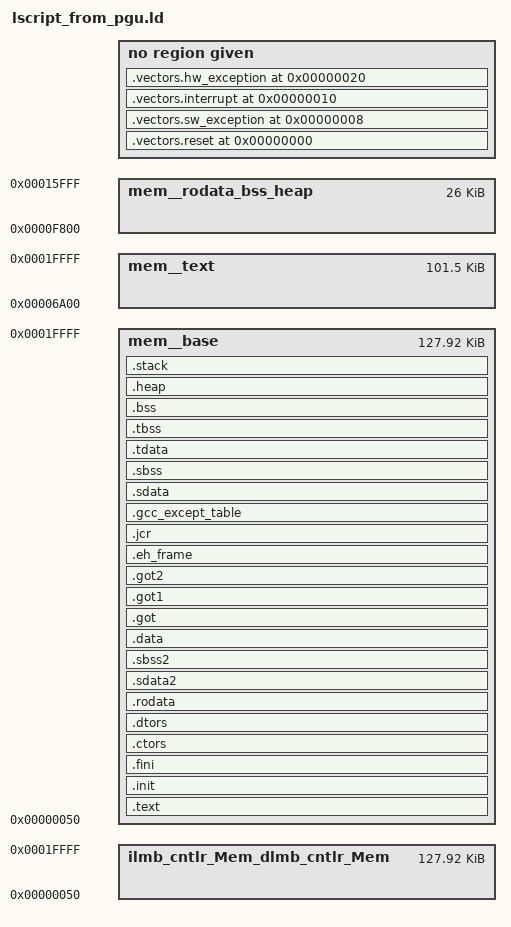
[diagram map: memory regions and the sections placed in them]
/*******************************************************************/
/*                                                                 */
/* This file is automatically generated by linker script generator.*/
/*                                                                 */
/* Version:                                 */
/*                                                                 */
/* Copyright (c) 2010-2016 Xilinx, Inc.  All rights reserved.      */
/*                                                                 */
/* Description : MicroBlaze Linker Script                          */
/*                                                                 */
/*******************************************************************/

_STACK_SIZE = DEFINED(_STACK_SIZE) ? _STACK_SIZE : 0x340;
_HEAP_SIZE = DEFINED(_HEAP_SIZE) ? _HEAP_SIZE : 0x18;

/* Define Memories in the system */

MEMORY
{
   ilmb_cntlr_Mem_dlmb_cntlr_Mem : ORIGIN = 0x50, LENGTH = 0x1FFB0
   mem__rodata_bss_heap  : ORIGIN = 0x0F800, LENGTH = 0x06800
   mem__text  : ORIGIN = 0x06A00, LENGTH = 0x19600
   mem__base  : ORIGIN = 0x50, LENGTH = 0x1FFB0
}

/* Specify the default entry point to the program */

ENTRY(_start)

/* Define the sections, and where they are mapped in memory */

SECTIONS
{
.vectors.reset 0x0 : {
   KEEP (*(.vectors.reset))
} 

.vectors.sw_exception 0x8 : {
   KEEP (*(.vectors.sw_exception))
} 

.vectors.interrupt 0x10 : {
   KEEP (*(.vectors.interrupt))
} 

.vectors.hw_exception 0x20 : {
   KEEP (*(.vectors.hw_exception))
} 

.text : {
   *(.text)
   *(.text.*)
   *(.gnu.linkonce.t.*)
} > mem__base

.init : {
   KEEP (*(.init))
} > mem__base

.fini : {
   KEEP (*(.fini))
} > mem__base

.ctors : {
   __CTOR_LIST__ = .;
   ___CTORS_LIST___ = .;
   KEEP (*crtbegin.o(.ctors))
   KEEP (*(EXCLUDE_FILE(*crtend.o) .ctors))
   KEEP (*(SORT(.ctors.*)))
   KEEP (*(.ctors))
   __CTOR_END__ = .;
   ___CTORS_END___ = .;
} > mem__base

.dtors : {
   __DTOR_LIST__ = .;
   ___DTORS_LIST___ = .;
   KEEP (*crtbegin.o(.dtors))
   KEEP (*(EXCLUDE_FILE(*crtend.o) .dtors))
   KEEP (*(SORT(.dtors.*)))
   KEEP (*(.dtors))
   PROVIDE(__DTOR_END__ = .);
   PROVIDE(___DTORS_END___ = .);
} > mem__base

.rodata : {
   __rodata_start = .;
   *(.rodata)
   *(.rodata.*)
   *(.gnu.linkonce.r.*)
   __rodata_end = .;
} > mem__base

.sdata2 : {
   . = ALIGN(8);
   __sdata2_start = .;
   *(.sdata2)
   *(.sdata2.*)
   *(.gnu.linkonce.s2.*)
   . = ALIGN(8);
   __sdata2_end = .;
} > mem__base

.sbss2 : {
   __sbss2_start = .;
   *(.sbss2)
   *(.sbss2.*)
   *(.gnu.linkonce.sb2.*)
   __sbss2_end = .;
} > mem__base

.data : {
   . = ALIGN(4);
   __data_start = .;
   *(.data)
   *(.data.*)
   *(.gnu.linkonce.d.*)
   __data_end = .;
} > mem__base

.got : {
   *(.got)
} > mem__base

.got1 : {
   *(.got1)
} > mem__base

.got2 : {
   *(.got2)
} > mem__base

.eh_frame : {
   *(.eh_frame)
} > mem__base

.jcr : {
   *(.jcr)
} > mem__base

.gcc_except_table : {
   *(.gcc_except_table)
} > mem__base

.sdata : {
   . = ALIGN(8);
   __sdata_start = .;
   *(.sdata)
   *(.sdata.*)
   *(.gnu.linkonce.s.*)
   __sdata_end = .;
} > mem__base

.sbss (NOLOAD) : {
   . = ALIGN(4);
   __sbss_start = .;
   *(.sbss)
   *(.sbss.*)
   *(.gnu.linkonce.sb.*)
   . = ALIGN(8);
   __sbss_end = .;
} > mem__base

.tdata : {
   __tdata_start = .;
   *(.tdata)
   *(.tdata.*)
   *(.gnu.linkonce.td.*)
   __tdata_end = .;
} > mem__base

.tbss : {
   __tbss_start = .;
   *(.tbss)
   *(.tbss.*)
   *(.gnu.linkonce.tb.*)
   __tbss_end = .;
} > mem__base

.bss (NOLOAD) : {
   . = ALIGN(4);
   __bss_start = .;
   *(.bss)
   *(.bss.*)
   *(.gnu.linkonce.b.*)
   *(COMMON)
   . = ALIGN(4);
   __bss_end = .;
} > mem__base

_SDA_BASE_ = __sdata_start + ((__sbss_end - __sdata_start) / 2 );

_SDA2_BASE_ = __sdata2_start + ((__sbss2_end - __sdata2_start) / 2 );

/* Generate Stack and Heap definitions */

.heap (NOLOAD) : {
   . = ALIGN(8);
   _heap = .;
   _heap_start = .;
   . += _HEAP_SIZE;
   _heap_end = .;
} > mem__base

.stack (NOLOAD) : {
   _stack_end = .;
   . += _STACK_SIZE;
   . = ALIGN(8);
   _stack = .;
   __stack = _stack;
} > mem__base

_end = .;
}

